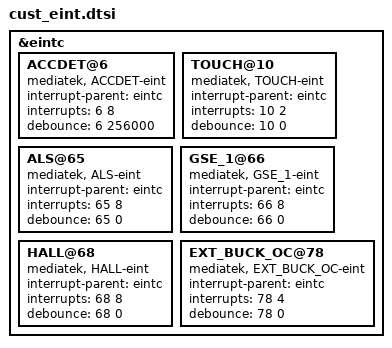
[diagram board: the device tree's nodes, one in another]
/*
 * Generated by MTK SP DrvGen Version 03.13.6 for MT6735M. Copyright MediaTek Inc. (C) 2013.
 * Thu Aug 11 20:15:14 2016
 * Do Not Modify the File.
 */

/*************************
 * EINT DTSI File
*************************/

&eintc {
	ACCDET@6 {
		compatible = "mediatek, ACCDET-eint";
		interrupt-parent = <&eintc>;
		interrupts = <6 8>;
		debounce = <6 256000>;
	};

	TOUCH@10 {
		compatible = "mediatek, TOUCH-eint";
		interrupt-parent = <&eintc>;
		interrupts = <10 2>;
		debounce = <10 0>;
	};

	ALS@65 {
		compatible = "mediatek, ALS-eint";
		interrupt-parent = <&eintc>;
		interrupts = <65 8>;
		debounce = <65 0>;
	};

	GSE_1@66 {
		compatible = "mediatek, GSE_1-eint";
		interrupt-parent = <&eintc>;
		interrupts = <66 8>;
		debounce = <66 0>;
	};

	HALL@68 {
		compatible = "mediatek, HALL-eint";
		interrupt-parent = <&eintc>;
		interrupts = <68 8>;
		debounce = <68 0>;
	};

	EXT_BUCK_OC@78 {
		compatible = "mediatek, EXT_BUCK_OC-eint";
		interrupt-parent = <&eintc>;
		interrupts = <78 4>;
		debounce = <78 0>;
	};

};
